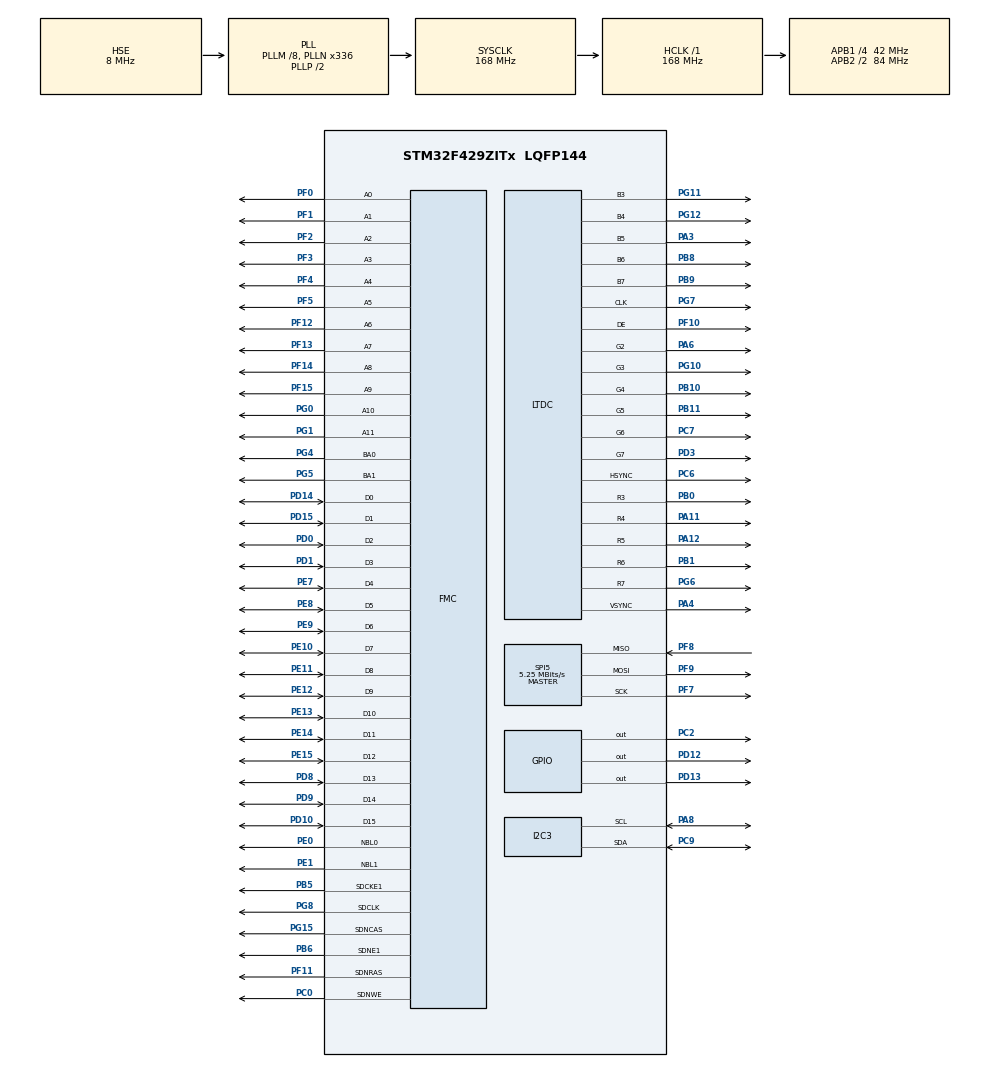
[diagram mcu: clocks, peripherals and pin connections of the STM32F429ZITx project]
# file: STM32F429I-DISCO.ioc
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PA11.GPIO_Speed=GPIO_SPEED_FREQ_HIGH
SH.FMC_D7_DA7.0=FMC_D7,sd-16b-d1
VP_SYS_VS_tim6.Mode=TIM6
FMC.RCDDelay1=2
FMC.SDClockPeriod1=FMC_SDRAM_CLOCK_PERIOD_2
SH.FMC_A0.0=FMC_A0,12b-sda1
PB10.Mode=RGB565
VP_ADC1_TempSens_Input.Mode=IN-TempSens
NVIC.TIM6_DAC_IRQn=true\:0\:0\:false\:false\:true\:false\:false\:true
PG4.Signal=FMC_A14_BA0
PG8.Signal=FMC_SDCLK
PG0.Signal=FMC_A10
FMC.LoadToActiveDelay1=2
SH.FMC_D5_DA5.0=FMC_D5,sd-16b-d1
PA3.GPIO_Speed=GPIO_SPEED_FREQ_HIGH
PD3.GPIO_Speed=GPIO_SPEED_FREQ_HIGH
VP_STMicroelectronics.X-CUBE-TOUCHGFX_VS_GraphicsJjApplication_4.16.0.Mode=GraphicsJjApplication
PG6.Mode=RGB565
RCC.SYSCLKSource=RCC_SYSCLKSOURCE_PLLCLK
PB11.GPIO_Speed=GPIO_SPEED_FREQ_HIGH
SH.FMC_A15_BA1.0=FMC_BA1,FourSdramBanks1
SH.FMC_D9_DA9.0=FMC_D9,sd-16b-d1
STMicroelectronics.X-CUBE-TOUCHGFX.4.16.0.tgfx_hardware_accelerator=dma_2d
PA4.Mode=RGB565
PF7.Signal=SPI5_SCK
NVIC.DMA2D_IRQn=true\:5\:0\:true\:false\:true\:false\:true\:true
SH.FMC_SDNWE.0=FMC_SDNWE,12b-sda1
SH.FMC_D11_DA11.0=FMC_D11,sd-16b-d1
RCC.APB2TimFreq_Value=168000000
PB6.Signal=FMC_SDNE1
PC7.Signal=LTDC_G6
ADC1.InjNumberOfConversion=0
PH1/OSC_OUT.Signal=RCC_OSC_OUT
PB6.Mode=SdramChipSelect2_1
PD0.Signal=FMC_D2_DA2
PD8.Signal=FMC_D13_DA13
PE1.Signal=FMC_NBL1
I2C3.Analog_Filter=I2C_ANALOGFILTER_DISABLE
FMC.SelfRefreshTime1=4
LTDC.PixelFormat_L0=LTDC_PIXEL_FORMAT_RGB565
PE9.Signal=FMC_D6_DA6
PB1.GPIO_Speed=GPIO_SPEED_FREQ_HIGH
SH.FMC_A2.0=FMC_A2,12b-sda1
PC9.Mode=I2C
PF8.Mode=Full_Duplex_Master
PA8.Signal=I2C3_SCL
SH.FMC_D1_DA1.0=FMC_D1,sd-16b-d1
PF3.Signal=FMC_A3
PD3.Mode=RGB565
PE10.Signal=FMC_D7_DA7
LTDC.HSync=10
ADC1.SamplingTime-0\#ChannelRegularConversion=ADC_SAMPLETIME_28CYCLES
Mcu.Package=LQFP144
PB9.Signal=LTDC_B7
PB1.Signal=LTDC_R6
NVIC.TimeBase=TIM6_DAC_IRQn
PD12.Signal=GPIO_Output
NVIC.TimeBaseIP=TIM6
FMC.WriteRecoveryTime1=3
SH.FMC_A1.0=FMC_A1,12b-sda1
SPI5.CalculateBaudRate=5.25 MBits/s
RCC.APB2CLKDivider=RCC_HCLK_DIV2
SH.FMC_SDCLK.0=FMC_SDCLK,12b-sda1
LTDC.VSync=2
PF14.Signal=FMC_A8
RCC.APB1TimFreq_Value=84000000
VP_DMA2D_VS_DMA2D.Mode=DMA2D_Activate
PF10.Mode=RGB565
FMC.RowCycleDelay1=7
PA6.GPIO_Speed=GPIO_SPEED_FREQ_HIGH
PC6.GPIO_Speed=GPIO_SPEED_FREQ_HIGH
PD15.Signal=FMC_D1_DA1
SH.FMC_D3_DA3.0=FMC_D3,sd-16b-d1
SPI5.VirtualType=VM_MASTER
PG6.GPIO_Speed=GPIO_SPEED_FREQ_HIGH
PG12.Signal=LTDC_B4
SH.FMC_A4.0=FMC_A4,12b-sda1
FREERTOS.Tasks01=GUI_Task,24,8192,TouchGFX_Task,As weak,NULL,Dynamic,NULL,NULL
ADC1.Rank-0\#ChannelRegularConversion=1
PG5.Signal=FMC_A15_BA1
SH.FMC_D10_DA10.0=FMC_D10,sd-16b-d1
PD3.Signal=LTDC_G7
PC6.Signal=LTDC_HSYNC
PC2.Signal=GPIO_Output
PD1.Signal=FMC_D3_DA3
STMicroelectronics.X-CUBE-TOUCHGFX.4.16.0.tgfx_buffering_strategy=Double
PC0.Signal=FMC_SDNWE
RCC.APB1CLKDivider=RCC_HCLK_DIV4
PG10.Signal=LTDC_G3
LTDC.ImageWidth_L0=240
PD10.Signal=FMC_D15_DA15
PA3.Mode=RGB565
SH.FMC_A3.0=FMC_A3,12b-sda1
FMC.CASLatency1=FMC_SDRAM_CAS_LATENCY_3
PB11.Mode=RGB565
FREERTOS.configMAX_PRIORITIES=56
SH.FMC_D15_DA15.0=FMC_D15,sd-16b-d1
PC6.Mode=RGB565
PB10.Signal=LTDC_G4
SH.FMC_A6.0=FMC_A6,12b-sda1
PE14.Signal=FMC_D11_DA11
LTDC.Blue_L0=0
PE15.Signal=FMC_D12_DA12
PE8.Signal=FMC_D5_DA5
PF13.Signal=FMC_A7
SH.FMC_SDNCAS.0=FMC_SDNCAS,12b-sda1
PA4.Signal=LTDC_VSYNC
PB5.Signal=FMC_SDCKE1
ADC1.master=1
SH.FMC_A5.0=FMC_A5,12b-sda1
PG11.Mode=RGB565
LTDC.Alpha_L0=255
PA11.Signal=LTDC_R4
ProjectManager.HeapSize=0xA00
PB1.Mode=RGB565
PG12.GPIO_Speed=GPIO_SPEED_FREQ_HIGH
PF9.Signal=SPI5_MOSI
STMicroelectronics.X-CUBE-TOUCHGFX.4.16.0.tgfx_vsync=vsync_ltdc
NVIC.PriorityGroup=NVIC_PRIORITYGROUP_4
PB8.Mode=RGB565
PA8.Mode=I2C
PF4.Signal=FMC_A4
PB0.Signal=LTDC_R3
Mcu.Family=STM32F4
LTDC.BlendingFactor1_L0=LTDC_BLENDING_FACTOR1_CA
PA6.Mode=RGB565
SH.FMC_A8.0=FMC_A8,12b-sda1
RCC.CortexFreq_Value=168000000
PG6.Signal=LTDC_R7
PB10.GPIO_Speed=GPIO_SPEED_FREQ_HIGH
RCC.PLLSAIDivR=RCC_PLLSAIDIVR_8
SH.FMC_D14_DA14.0=FMC_D14,sd-16b-d1
LTDC.HBP=20
SH.FMC_NBL0.0=FMC_NBL0,Sd2ByteEnable1
SH.FMC_D6_DA6.0=FMC_D6,sd-16b-d1
PA11.Mode=RGB565
PC2.GPIO_Speed=GPIO_SPEED_FREQ_HIGH
SH.FMC_A14_BA0.0=FMC_BA0,FourSdramBanks1
SH.FMC_A11.0=FMC_A11,12b-sda1
PB11.Signal=LTDC_G5
PG11.Signal=LTDC_B3
PG15.Signal=FMC_SDNCAS
ProjectManager.StackSize=0xA00
VP_FREERTOS_VS_CMSIS_V2.Mode=CMSIS_V2
PD13.Signal=GPIO_Output
SH.FMC_A7.0=FMC_A7,12b-sda1
PA12.Signal=LTDC_R5
PH0/OSC_IN.Mode=HSE-External-Oscillator
RCC.HCLKFreq_Value=168000000
SH.FMC_NBL1.0=FMC_NBL1,Sd2ByteEnable1
LTDC.WindowX1_L0=240
PF12.Signal=FMC_A6
SPI5.CLKPolarity=SPI_POLARITY_LOW
SH.FMC_A10.0=FMC_A10,12b-sda1
RCC.AHBFreq_Value=168000000
ADC1.Channel-0\#ChannelRegularConversion=ADC_CHANNEL_TEMPSENSOR
RCC.HSE_VALUE=8000000
STMicroelectronics.X-CUBE-TOUCHGFX.4.16.0.tgfx_display_interface=disp_ltdc
SH.FMC_D8_DA8.0=FMC_D8,sd-16b-d1
FMC.ExitSelfRefreshDelay1=7
FMC.RPDelay1=2
PA4.GPIO_Speed=GPIO_SPEED_FREQ_HIGH
SH.FMC_D2_DA2.0=FMC_D2,sd-16b-d1
PG11.GPIO_Speed=GPIO_SPEED_FREQ_HIGH
PF9.Mode=Full_Duplex_Master
PE13.Signal=FMC_D10_DA10
PF11.Signal=FMC_SDNRAS
PB5.Mode=SdramChipSelect2_1
LTDC.HFP=10
LTDC.BlendingFactor2_L0=LTDC_BLENDING_FACTOR2_CA
FMC.ReadPipeDelay1=FMC_SDRAM_RPIPE_DELAY_1
SH.FMC_SDNRAS.0=FMC_SDNRAS,12b-sda1
DMA2D.ColorMode=DMA2D_OUTPUT_RGB565
LTDC.ActiveW=240
PH1/OSC_OUT.Mode=HSE-External-Oscillator
FREERTOS.configTOTAL_HEAP_SIZE=65536
SPI5.BaudRatePrescaler=SPI_BAUDRATEPRESCALER_16
PA6.Signal=LTDC_G2
SH.FMC_D0_DA0.0=FMC_D0,sd-16b-d1
SH.FMC_A9.0=FMC_A9,12b-sda1
PF8.Signal=SPI5_MISO
SH.FMC_D4_DA4.0=FMC_D4,sd-16b-d1
RCC.PLLSAIN=192
PF5.Signal=FMC_A5
RCC.PLLSAIR=4
PB9.GPIO_Speed=GPIO_SPEED_FREQ_HIGH
PF0.Signal=FMC_A0
PE7.Signal=FMC_D4_DA4
PA12.GPIO_Speed=GPIO_SPEED_FREQ_HIGH
PA3.Signal=LTDC_B5
RCC.PLLSourceVirtual=RCC_PLLSOURCE_HSE
NVIC.LTDC_IRQn=true\:5\:0\:true\:false\:true\:false\:true\:true
LTDC.VFP=4
PD12.GPIO_Speed=GPIO_SPEED_FREQ_HIGH
LTDC.WindowY1_L0=320
PG7.Signal=LTDC_CLK
PG1.Signal=FMC_A11
PF10.GPIO_Speed=GPIO_SPEED_FREQ_HIGH
PG10.Mode=RGB565
PD9.Signal=FMC_D14_DA14
FREERTOS.configUSE_APPLICATION_TASK_TAG=1
PG10.GPIO_Speed=GPIO_SPEED_FREQ_HIGH
SPI5.Mode=SPI_MODE_MASTER
PB0.GPIO_Speed=GPIO_SPEED_FREQ_HIGH
PF7.Mode=Full_Duplex_Master
ProjectManager.TargetToolchain=STM32CubeIDE
SH.FMC_D13_DA13.0=FMC_D13,sd-16b-d1
LTDC.ActiveH=320
PB9.Mode=RGB565
PF2.Signal=FMC_A2
STMicroelectronics.X-CUBE-TOUCHGFX.4.16.0.ApplicationCcGraphicsJjApplication=TouchGFXOoGenerator
PE11.Signal=FMC_D8_DA8
PG7.Mode=RGB565
RCC.LSE_VALUE=32768
PB0.Mode=RGB565
board=custom
PD13.GPIO_Speed=GPIO_SPEED_FREQ_HIGH
PG12.Mode=RGB565
PC7.GPIO_Speed=GPIO_SPEED_FREQ_HIGH
RCC.VCOOutputFreq_Value=336000000
PH0/OSC_IN.Signal=RCC_OSC_IN
PG7.GPIO_Speed=GPIO_SPEED_FREQ_HIGH
RCC.APB2Freq_Value=84000000
LTDC.Layers=0
PF10.Signal=LTDC_DE
SH.FMC_D12_DA12.0=FMC_D12,sd-16b-d1
PF15.Signal=FMC_A9
PF1.Signal=FMC_A1
Mcu.Name=STM32F429ZITx
PE0.Signal=FMC_NBL0
PE12.Signal=FMC_D9_DA9
PD14.Signal=FMC_D0_DA0
RCC.48MHZClocksFreq_Value=84000000
RCC.SYSCLKFreq_VALUE=168000000
PA12.Mode=RGB565
SPI5.CRCCalculation=SPI_CRCCALCULATION_DISABLE
RCC.HSI_VALUE=16000000
ADC1.NbrOfConversionFlag=1
RCC.PLLM=8
RCC.PLLN=336
PB8.Signal=LTDC_B6
PC9.Signal=I2C3_SDA
PC7.Mode=RGB565
RCC.APB1Freq_Value=42000000
PB8.GPIO_Speed=GPIO_SPEED_FREQ_HIGH
VP_CRC_VS_CRC.Mode=CRC_Activate
LTDC.ImageHeight_L0=320
ADC1.ClockPrescaler=ADC_CLOCK_SYNC_PCLK_DIV8
SPI5.Direction=SPI_DIRECTION_2LINES

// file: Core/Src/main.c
/* USER CODE BEGIN Header */
/**
  ******************************************************************************
  * @file           : main.c
  * @brief          : Main program body
  ******************************************************************************
  * @attention
  *
  * <h2><center>&copy; Copyright (c) 2021 STMicroelectronics.
  * All rights reserved.</center></h2>
  *
  * This software component is licensed by ST under Ultimate Liberty license
  * SLA0044, the "License"; You may not use this file except in compliance with
  * the License. You may obtain a copy of the License at:
  *                             www.st.com/SLA0044
  *
  ******************************************************************************
  */
/* USER CODE END Header */

#include "main.h"
#include "cmsis_os.h"
#include "app_touchgfx.h"

ADC_HandleTypeDef hadc1;

CRC_HandleTypeDef hcrc;

DMA2D_HandleTypeDef hdma2d;

I2C_HandleTypeDef hi2c3;

LTDC_HandleTypeDef hltdc;

SPI_HandleTypeDef hspi5;

SDRAM_HandleTypeDef hsdram1;

/* Definitions for GUI_Task */
osThreadId_t GUI_TaskHandle;
const osThreadAttr_t GUI_Task_attributes = {
  .name = "GUI_Task",
  .priority = (osPriority_t) osPriorityNormal,
  .stack_size = 8192 * 4
};

void SystemClock_Config(void);
static void MX_GPIO_Init(void);
static void MX_CRC_Init(void);
static void MX_I2C3_Init(void);
static void MX_SPI5_Init(void);
static void MX_FMC_Init(void);
static void MX_LTDC_Init(void);
static void MX_DMA2D_Init(void);
static void MX_ADC1_Init(void);
void TouchGFX_Task(void *argument);

int main(void)
{

  /* MCU Configuration--------------------------------------------------------*/

  /* Reset of all peripherals, Initializes the Flash interface and the Systick. */
  HAL_Init();

  /* Configure the system clock */
  SystemClock_Config();

  /* Initialize all configured peripherals */
  MX_GPIO_Init();
  MX_CRC_Init();
  MX_I2C3_Init();
  MX_SPI5_Init();
  MX_FMC_Init();
  MX_LTDC_Init();
  MX_DMA2D_Init();
  MX_ADC1_Init();
  MX_TouchGFX_Init();

  /* Init scheduler */
  osKernelInitialize();

  /* Create the thread(s) */
  /* creation of GUI_Task */
  GUI_TaskHandle = osThreadNew(TouchGFX_Task, NULL, &GUI_Task_attributes);

  /* Start scheduler */
  osKernelStart();

  /* We should never get here as control is now taken by the scheduler */
  /* Infinite loop */
  while (1)
  {

  }
}

void SystemClock_Config(void)
{
  RCC_OscInitTypeDef RCC_OscInitStruct = {0};
  RCC_ClkInitTypeDef RCC_ClkInitStruct = {0};
  RCC_PeriphCLKInitTypeDef PeriphClkInitStruct = {0};

  /** Configure the main internal regulator output voltage
  */
  __HAL_RCC_PWR_CLK_ENABLE();
  __HAL_PWR_VOLTAGESCALING_CONFIG(PWR_REGULATOR_VOLTAGE_SCALE1);
  /** Initializes the RCC Oscillators according to the specified parameters
  * in the RCC_OscInitTypeDef structure.
  */
  RCC_OscInitStruct.OscillatorType = RCC_OSCILLATORTYPE_HSE;
  RCC_OscInitStruct.HSEState = RCC_HSE_ON;
  RCC_OscInitStruct.PLL.PLLState = RCC_PLL_ON;
  RCC_OscInitStruct.PLL.PLLSource = RCC_PLLSOURCE_HSE;
  RCC_OscInitStruct.PLL.PLLM = 8;
  RCC_OscInitStruct.PLL.PLLN = 336;
  RCC_OscInitStruct.PLL.PLLP = RCC_PLLP_DIV2;
  RCC_OscInitStruct.PLL.PLLQ = 4;
  if (HAL_RCC_OscConfig(&RCC_OscInitStruct) != HAL_OK)
  {
    Error_Handler();
  }
  /** Initializes the CPU, AHB and APB buses clocks
  */
  RCC_ClkInitStruct.ClockType = RCC_CLOCKTYPE_HCLK|RCC_CLOCKTYPE_SYSCLK
                              |RCC_CLOCKTYPE_PCLK1|RCC_CLOCKTYPE_PCLK2;
  RCC_ClkInitStruct.SYSCLKSource = RCC_SYSCLKSOURCE_PLLCLK;
  RCC_ClkInitStruct.AHBCLKDivider = RCC_SYSCLK_DIV1;
  RCC_ClkInitStruct.APB1CLKDivider = RCC_HCLK_DIV4;
  RCC_ClkInitStruct.APB2CLKDivider = RCC_HCLK_DIV2;

  if (HAL_RCC_ClockConfig(&RCC_ClkInitStruct, FLASH_LATENCY_5) != HAL_OK)
  {
    Error_Handler();
  }
  PeriphClkInitStruct.PeriphClockSelection = RCC_PERIPHCLK_LTDC;
  PeriphClkInitStruct.PLLSAI.PLLSAIN = 192;
  PeriphClkInitStruct.PLLSAI.PLLSAIR = 4;
  PeriphClkInitStruct.PLLSAIDivR = RCC_PLLSAIDIVR_8;
  if (HAL_RCCEx_PeriphCLKConfig(&PeriphClkInitStruct) != HAL_OK)
  {
    Error_Handler();
  }
}

static void MX_ADC1_Init(void)
{

  ADC_ChannelConfTypeDef sConfig = {0};

  /** Configure the global features of the ADC (Clock, Resolution, Data Alignment and number of conversion)
  */
  hadc1.Instance = ADC1;
  hadc1.Init.ClockPrescaler = ADC_CLOCK_SYNC_PCLK_DIV8;
  hadc1.Init.Resolution = ADC_RESOLUTION_12B;
  hadc1.Init.ScanConvMode = DISABLE;
  hadc1.Init.ContinuousConvMode = DISABLE;
  hadc1.Init.DiscontinuousConvMode = DISABLE;
  hadc1.Init.ExternalTrigConvEdge = ADC_EXTERNALTRIGCONVEDGE_NONE;
  hadc1.Init.ExternalTrigConv = ADC_SOFTWARE_START;
  hadc1.Init.DataAlign = ADC_DATAALIGN_RIGHT;
  hadc1.Init.NbrOfConversion = 1;
  hadc1.Init.DMAContinuousRequests = DISABLE;
  hadc1.Init.EOCSelection = ADC_EOC_SINGLE_CONV;
  if (HAL_ADC_Init(&hadc1) != HAL_OK)
  {
    Error_Handler();
  }
  /** Configure for the selected ADC regular channel its corresponding rank in the sequencer and its sample time.
  */
  sConfig.Channel = ADC_CHANNEL_TEMPSENSOR;
  sConfig.Rank = 1;
  sConfig.SamplingTime = ADC_SAMPLETIME_28CYCLES;
  if (HAL_ADC_ConfigChannel(&hadc1, &sConfig) != HAL_OK)
  {
    Error_Handler();
  }

}

static void MX_CRC_Init(void)
{

  hcrc.Instance = CRC;
  if (HAL_CRC_Init(&hcrc) != HAL_OK)
  {
    Error_Handler();
  }

}

static void MX_DMA2D_Init(void)
{

  hdma2d.Instance = DMA2D;
  hdma2d.Init.Mode = DMA2D_M2M;
  hdma2d.Init.ColorMode = DMA2D_OUTPUT_RGB565;
  hdma2d.Init.OutputOffset = 0;
  hdma2d.LayerCfg[1].InputOffset = 0;
  hdma2d.LayerCfg[1].InputColorMode = DMA2D_INPUT_RGB565;
  hdma2d.LayerCfg[1].AlphaMode = DMA2D_NO_MODIF_ALPHA;
  hdma2d.LayerCfg[1].InputAlpha = 0;
  if (HAL_DMA2D_Init(&hdma2d) != HAL_OK)
  {
    Error_Handler();
  }
  if (HAL_DMA2D_ConfigLayer(&hdma2d, 1) != HAL_OK)
  {
    Error_Handler();
  }

}

static void MX_I2C3_Init(void)
{

  hi2c3.Instance = I2C3;
  hi2c3.Init.ClockSpeed = 100000;
  hi2c3.Init.DutyCycle = I2C_DUTYCYCLE_2;
  hi2c3.Init.OwnAddress1 = 0;
  hi2c3.Init.AddressingMode = I2C_ADDRESSINGMODE_7BIT;
  hi2c3.Init.DualAddressMode = I2C_DUALADDRESS_DISABLE;
  hi2c3.Init.OwnAddress2 = 0;
  hi2c3.Init.GeneralCallMode = I2C_GENERALCALL_DISABLE;
  hi2c3.Init.NoStretchMode = I2C_NOSTRETCH_DISABLE;
  if (HAL_I2C_Init(&hi2c3) != HAL_OK)
  {
    Error_Handler();
  }
  /** Configure Analogue filter
  */
  if (HAL_I2CEx_ConfigAnalogFilter(&hi2c3, I2C_ANALOGFILTER_DISABLE) != HAL_OK)
  {
    Error_Handler();
  }
  /** Configure Digital filter
  */
  if (HAL_I2CEx_ConfigDigitalFilter(&hi2c3, 0) != HAL_OK)
  {
    Error_Handler();
  }

}

static void MX_LTDC_Init(void)
{

  LTDC_LayerCfgTypeDef pLayerCfg = {0};
  LTDC_LayerCfgTypeDef pLayerCfg1 = {0};

  hltdc.Instance = LTDC;
  hltdc.Init.HSPolarity = LTDC_HSPOLARITY_AL;
  hltdc.Init.VSPolarity = LTDC_VSPOLARITY_AL;
  hltdc.Init.DEPolarity = LTDC_DEPOLARITY_AL;
  hltdc.Init.PCPolarity = LTDC_PCPOLARITY_IPC;
  hltdc.Init.HorizontalSync = 9;
  hltdc.Init.VerticalSync = 1;
  hltdc.Init.AccumulatedHBP = 29;
  hltdc.Init.AccumulatedVBP = 3;
  hltdc.Init.AccumulatedActiveW = 269;
  hltdc.Init.AccumulatedActiveH = 323;
  hltdc.Init.TotalWidth = 279;
  hltdc.Init.TotalHeigh = 327;
  hltdc.Init.Backcolor.Blue = 0;
  hltdc.Init.Backcolor.Green = 0;
  hltdc.Init.Backcolor.Red = 0;
  if (HAL_LTDC_Init(&hltdc) != HAL_OK)
  {
    Error_Handler();
  }
  pLayerCfg.WindowX0 = 0;
  pLayerCfg.WindowX1 = 240;
  pLayerCfg.WindowY0 = 0;
  pLayerCfg.WindowY1 = 320;
  pLayerCfg.PixelFormat = LTDC_PIXEL_FORMAT_RGB565;
  pLayerCfg.Alpha = 255;
  pLayerCfg.Alpha0 = 0;
  pLayerCfg.BlendingFactor1 = LTDC_BLENDING_FACTOR1_CA;
  pLayerCfg.BlendingFactor2 = LTDC_BLENDING_FACTOR2_CA;
  pLayerCfg.FBStartAdress = 0;
  pLayerCfg.ImageWidth = 240;
  pLayerCfg.ImageHeight = 320;
  pLayerCfg.Backcolor.Blue = 0;
  pLayerCfg.Backcolor.Green = 0;
  pLayerCfg.Backcolor.Red = 0;
  if (HAL_LTDC_ConfigLayer(&hltdc, &pLayerCfg, 0) != HAL_OK)
  {
    Error_Handler();
  }
  pLayerCfg1.WindowX0 = 0;
  pLayerCfg1.WindowX1 = 0;
  pLayerCfg1.WindowY0 = 0;
  pLayerCfg1.WindowY1 = 0;
  pLayerCfg1.Alpha = 0;
  pLayerCfg1.Alpha0 = 0;
  pLayerCfg1.BlendingFactor1 = LTDC_BLENDING_FACTOR1_CA;
  pLayerCfg1.BlendingFactor2 = LTDC_BLENDING_FACTOR2_CA;
  pLayerCfg1.FBStartAdress = 0;
  pLayerCfg1.ImageWidth = 0;
  pLayerCfg1.ImageHeight = 0;
  pLayerCfg1.Backcolor.Blue = 0;
  pLayerCfg1.Backcolor.Green = 0;
  pLayerCfg1.Backcolor.Red = 0;
  if (HAL_LTDC_ConfigLayer(&hltdc, &pLayerCfg1, 1) != HAL_OK)
  {
    Error_Handler();
  }

}

static void MX_SPI5_Init(void)
{

  /* SPI5 parameter configuration*/
  hspi5.Instance = SPI5;
  hspi5.Init.Mode = SPI_MODE_MASTER;
  hspi5.Init.Direction = SPI_DIRECTION_2LINES;
  hspi5.Init.DataSize = SPI_DATASIZE_8BIT;
  hspi5.Init.CLKPolarity = SPI_POLARITY_LOW;
  hspi5.Init.CLKPhase = SPI_PHASE_1EDGE;
  hspi5.Init.NSS = SPI_NSS_SOFT;
  hspi5.Init.BaudRatePrescaler = SPI_BAUDRATEPRESCALER_16;
  hspi5.Init.FirstBit = SPI_FIRSTBIT_MSB;
  hspi5.Init.TIMode = SPI_TIMODE_DISABLE;
  hspi5.Init.CRCCalculation = SPI_CRCCALCULATION_DISABLE;
  hspi5.Init.CRCPolynomial = 10;
  if (HAL_SPI_Init(&hspi5) != HAL_OK)
  {
    Error_Handler();
  }

}

/* FMC initialization function */
static void MX_FMC_Init(void)
{

  FMC_SDRAM_TimingTypeDef SdramTiming = {0};

  /** Perform the SDRAM1 memory initialization sequence
  */
  hsdram1.Instance = FMC_SDRAM_DEVICE;
  /* hsdram1.Init */
  hsdram1.Init.SDBank = FMC_SDRAM_BANK2;
  hsdram1.Init.ColumnBitsNumber = FMC_SDRAM_COLUMN_BITS_NUM_8;
  hsdram1.Init.RowBitsNumber = FMC_SDRAM_ROW_BITS_NUM_12;
  hsdram1.Init.MemoryDataWidth = FMC_SDRAM_MEM_BUS_WIDTH_16;
  hsdram1.Init.InternalBankNumber = FMC_SDRAM_INTERN_BANKS_NUM_4;
  hsdram1.Init.CASLatency = FMC_SDRAM_CAS_LATENCY_3;
  hsdram1.Init.WriteProtection = FMC_SDRAM_WRITE_PROTECTION_DISABLE;
  hsdram1.Init.SDClockPeriod = FMC_SDRAM_CLOCK_PERIOD_2;
  hsdram1.Init.ReadBurst = FMC_SDRAM_RBURST_DISABLE;
  hsdram1.Init.ReadPipeDelay = FMC_SDRAM_RPIPE_DELAY_1;
  /* SdramTiming */
  SdramTiming.LoadToActiveDelay = 2;
  SdramTiming.ExitSelfRefreshDelay = 7;
  SdramTiming.SelfRefreshTime = 4;
  SdramTiming.RowCycleDelay = 7;
  SdramTiming.WriteRecoveryTime = 3;
  SdramTiming.RPDelay = 2;
  SdramTiming.RCDDelay = 2;

  if (HAL_SDRAM_Init(&hsdram1, &SdramTiming) != HAL_OK)
  {
    Error_Handler( );
  }

}

static void MX_GPIO_Init(void)
{
  GPIO_InitTypeDef GPIO_InitStruct = {0};

  /* GPIO Ports Clock Enable */
  __HAL_RCC_GPIOF_CLK_ENABLE();
  __HAL_RCC_GPIOH_CLK_ENABLE();
  __HAL_RCC_GPIOC_CLK_ENABLE();
  __HAL_RCC_GPIOA_CLK_ENABLE();
  __HAL_RCC_GPIOB_CLK_ENABLE();
  __HAL_RCC_GPIOG_CLK_ENABLE();
  __HAL_RCC_GPIOE_CLK_ENABLE();
  __HAL_RCC_GPIOD_CLK_ENABLE();

  /*Configure GPIO pin Output Level */
  HAL_GPIO_WritePin(GPIOC, GPIO_PIN_2, GPIO_PIN_RESET);

  /*Configure GPIO pin Output Level */
  HAL_GPIO_WritePin(GPIOD, GPIO_PIN_12|GPIO_PIN_13, GPIO_PIN_RESET);

  /*Configure GPIO pin : PC2 */
  GPIO_InitStruct.Pin = GPIO_PIN_2;
  GPIO_InitStruct.Mode = GPIO_MODE_OUTPUT_PP;
  GPIO_InitStruct.Pull = GPIO_NOPULL;
  GPIO_InitStruct.Speed = GPIO_SPEED_FREQ_HIGH;
  HAL_GPIO_Init(GPIOC, &GPIO_InitStruct);

  /*Configure GPIO pins : PD12 PD13 */
  GPIO_InitStruct.Pin = GPIO_PIN_12|GPIO_PIN_13;
  GPIO_InitStruct.Mode = GPIO_MODE_OUTPUT_PP;
  GPIO_InitStruct.Pull = GPIO_NOPULL;
  GPIO_InitStruct.Speed = GPIO_SPEED_FREQ_HIGH;
  HAL_GPIO_Init(GPIOD, &GPIO_InitStruct);

}

/* USER CODE BEGIN 4 */

#ifdef PES_TEMP_ENABLE
uint32_t TEMP_SENSOR_GetValue(void)
{
	#define TEMP110_CAL_VALUE   ((uint16_t*)((uint32_t)0x08FFF818))
	#define TEMP30_CAL_VALUE    ((uint16_t*)((uint32_t)0x08FFF814))
	#define TEMP110             110.0f
	#define TEMP30              30.0f

	if (HAL_ADC_Start(&hadc1) == HAL_OK)
	{
		if (HAL_ADC_PollForConversion(&hadc1, 1000) == HAL_OK)
		{
			return (int32_t)(((TEMP110 - TEMP30) *
            		(HAL_ADC_GetValue(&hadc1) - (*TEMP30_CAL_VALUE)))/
            		((*TEMP110_CAL_VALUE) - (*TEMP30_CAL_VALUE))
								+ TEMP30);
		}
	}
	return  0xFFFFFFFF;
}
#endif /*PES_TEMP_ENABLE*/

/* USER CODE END 4 */

__weak void TouchGFX_Task(void *argument)
{
  for(;;)
  {
    osDelay(1);
  }
}

void HAL_TIM_PeriodElapsedCallback(TIM_HandleTypeDef *htim)
{
  if (htim->Instance == TIM6) {
    HAL_IncTick();
  }
}

void Error_Handler(void)
{
}

/************************ (C) COPYRIGHT STMicroelectronics *****END OF FILE****/
